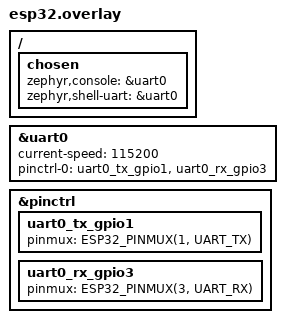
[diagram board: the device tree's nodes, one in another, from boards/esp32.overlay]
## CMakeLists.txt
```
cmake_minimum_required(VERSION 3.20.0)

# Specify the Zephyr base path
set(ZEPHYR_BASE C:/zephyrproject/zephyr)

# Find the Zephyr package
find_package(Zephyr REQUIRED HINTS ${ZEPHYR_BASE})

# Define the project
project(esp32_zephyr_attempt)

# Specify the source files
target_sources(app PRIVATE src/main.c)

# Optionally, include the source directory
target_include_directories(app PRIVATE src)

# Zephyr automatically includes Zephyr headers, so this is typically not necessary
# If needed, explicitly include Zephyr directories (though it's generally handled automatically)
# target_include_directories(app PRIVATE ${ZEPHYR_BASE}/include)

# Optional: To link any specific Zephyr libraries (if necessary)
# target_link_libraries(app PRIVATE zephyr)
```

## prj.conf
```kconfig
# Networking
CONFIG_NETWORKING=y
CONFIG_NET_IPV4=y
CONFIG_NET_UDP=y
CONFIG_NET_TCP=y
CONFIG_NET_DHCPV4=y
CONFIG_NET_SOCKETS=y

# Wi-Fi (ESP32)
CONFIG_WIFI=y
CONFIG_WIFI_ESP32=y

# Logging (opzionale)
CONFIG_LOG=y
CONFIG_WIFI_LOG_LEVEL_DBG=y
CONFIG_NET_LOG=y

# HTTP client
CONFIG_HTTP_CLIENT=y
CONFIG_TLS_CREDENTIALS=y

# TLS (opzionale se fai HTTPS)
CONFIG_MBEDTLS=y
CONFIG_MBEDTLS_ENABLE_HEAP=y
CONFIG_MBEDTLS_HEAP_SIZE=10240

# Abilita la funzionalità seriale
CONFIG_SERIAL=y

# Usa la UART come console
CONFIG_UART_CONSOLE=y

# Configurazione priorità console
CONFIG_CONSOLE_INIT_PRIORITY=3

# Abilitazione della UART per ESP32
CONFIG_UART_ESP32=y

# Configura i pin per UART2 se necessario, ma solo se lo usi
# In caso contrario, non configurarlo esplicitamente
# CONFIG_UART_2=y
```

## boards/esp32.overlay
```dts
/dts-v1/;

/ {
    chosen {
        zephyr,console = &uart0;
        zephyr,shell-uart = &uart0;
    };
};

&uart0 {
    status = "okay";
    current-speed = <115200>;
    pinctrl-0 = <&uart0_tx_gpio1 &uart0_rx_gpio3>;
    pinctrl-names = "default";
};

&pinctrl {
    uart0_tx_gpio1: uart0_tx_gpio1 {
        pinmux = <ESP32_PINMUX(1, UART_TX)>;
    };

    uart0_rx_gpio3: uart0_rx_gpio3 {
        pinmux = <ESP32_PINMUX(3, UART_RX)>;
    };
};
```

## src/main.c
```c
#include <zephyr/kernel.h>
#include <zephyr/device.h>
#include <zephyr/drivers/uart.h>
#include <zephyr/net/net_if.h>
#include <zephyr/net/wifi_mgmt.h>
#include <zephyr/net/socket.h>
#include <zephyr/logging/log.h>
#include <zephyr/data/json.h>
#include <zephyr/devicetree.h>
#include <zephyr/net/http/client.h>
#include <zephyr/net/net_event.h>
#include "secrets.h"

LOG_MODULE_REGISTER(main, LOG_LEVEL_DBG);

#define UART_NODE DT_NODELABEL(uart0)
#define BUFFER_SIZE 512

static const struct device *uart_dev;
static char uart_buffer[BUFFER_SIZE];
static int uart_pos = 0;

static void uart_cb(const struct device *dev, void *user_data) {
    uint8_t c;

    if (!uart_irq_update(dev) || !uart_irq_rx_ready(dev)) {
        return;
    }

    while (uart_fifo_read(dev, &c, 1)) {
        if (c == '\n') {
            uart_buffer[uart_pos] = '\0';
            uart_pos = 0;

            LOG_INF("Received line: %s", log_strdup(uart_buffer));
            // TODO: Parse JSON and send via HTTP
        } else if (uart_pos < BUFFER_SIZE - 1) {
            uart_buffer[uart_pos++] = c;
        }
    }
}

static void connect_to_wifi(void) {
    struct wifi_connect_req_params params = {
        .ssid = WIFI_SSID,
        .ssid_length = strlen(WIFI_SSID),
        .psk = WIFI_PASSWORD,
        .psk_length = strlen(WIFI_PASSWORD),
        .channel = WIFI_CHANNEL_ANY,
        .security = WIFI_SECURITY_TYPE_PSK,
    };

    struct net_if *iface = net_if_get_default();

    int ret = net_mgmt(NET_REQUEST_WIFI_CONNECT, iface, &params, sizeof(params));
    if (ret == 0) {
        LOG_INF("Wi-Fi connection initiated.");
    } else {
        LOG_ERR("Wi-Fi connection failed: %d", ret);
    }
}

void main(void) {
    LOG_INF("ESP32 Zephyr Weather Receiver");

    uart_dev = DEVICE_DT_GET(UART_NODE);
    if (!device_is_ready(uart_dev)) {
        LOG_ERR("UART device not ready");
        return;
    }

    uart_irq_callback_user_data_set(uart_dev, uart_cb, NULL);
    uart_irq_rx_enable(uart_dev);

    connect_to_wifi();

    while (1) {
        k_sleep(K_SECONDS(5));
    }
}
```
